VERSION ""

NS_ :

BS_:

BU_: BMS Charger

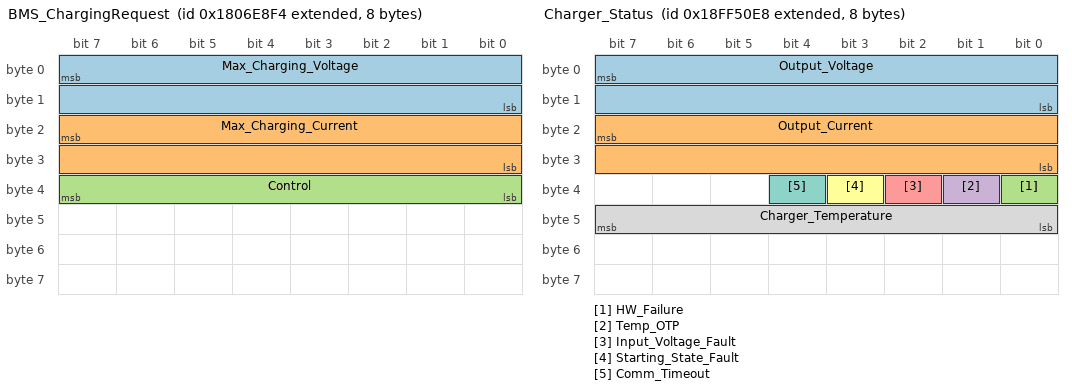
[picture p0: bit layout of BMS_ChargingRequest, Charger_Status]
BO_ 2550589684 BMS_ChargingRequest: 8 BMS
 SG_ Max_Charging_Voltage : 7|16@0+ (0.1,0) [0|6553.5] "V"  Charger
 SG_ Max_Charging_Current : 23|16@0+ (0.1,0) [0|6553.5] "A"  Charger
 SG_ Control : 32|8@1+ (1,0) [0|255] ""  Charger

BO_ 2566869224 Charger_Status: 8 Charger
 SG_ Output_Voltage : 7|16@0+ (0.1,0) [0|6553.5] "V"  BMS
 SG_ Output_Current : 23|16@0+ (0.1,0) [0|6553.5] "A"  BMS
 SG_ HW_Failure : 32|1@1+ (1,0) [0|1] ""  BMS
 SG_ Temp_OTP : 33|1@1+ (1,0) [0|1] ""  BMS
 SG_ Input_Voltage_Fault : 34|1@1+ (1,0) [0|1] ""  BMS
 SG_ Starting_State_Fault : 35|1@1+ (1,0) [0|1] ""  BMS
 SG_ Comm_Timeout : 36|1@1+ (1,0) [0|1] ""  BMS
 SG_ Charger_Temperature : 40|8@1+ (1,-40) [-40|215] "degC"  BMS

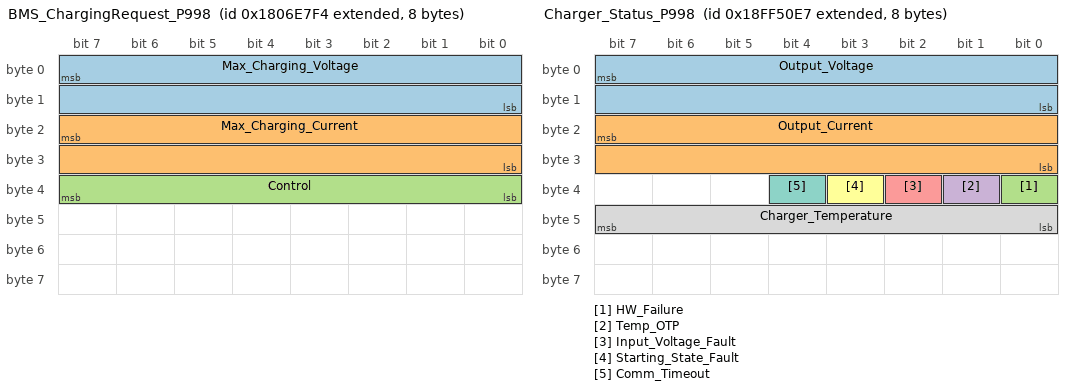
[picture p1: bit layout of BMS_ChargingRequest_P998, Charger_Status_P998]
BO_ 2550589428 BMS_ChargingRequest_P998: 8 BMS
 SG_ Max_Charging_Voltage : 7|16@0+ (0.1,0) [0|6553.5] "V"  Charger
 SG_ Max_Charging_Current : 23|16@0+ (0.1,0) [0|6553.5] "A"  Charger
 SG_ Control : 32|8@1+ (1,0) [0|255] ""  Charger

BO_ 2566869223 Charger_Status_P998: 8 Charger
 SG_ Output_Voltage : 7|16@0+ (0.1,0) [0|6553.5] "V"  BMS
 SG_ Output_Current : 23|16@0+ (0.1,0) [0|6553.5] "A"  BMS
 SG_ HW_Failure : 32|1@1+ (1,0) [0|1] ""  BMS
 SG_ Temp_OTP : 33|1@1+ (1,0) [0|1] ""  BMS
 SG_ Input_Voltage_Fault : 34|1@1+ (1,0) [0|1] ""  BMS
 SG_ Starting_State_Fault : 35|1@1+ (1,0) [0|1] ""  BMS
 SG_ Comm_Timeout : 36|1@1+ (1,0) [0|1] ""  BMS
 SG_ Charger_Temperature : 40|8@1+ (1,-40) [-40|215] "degC"  BMS

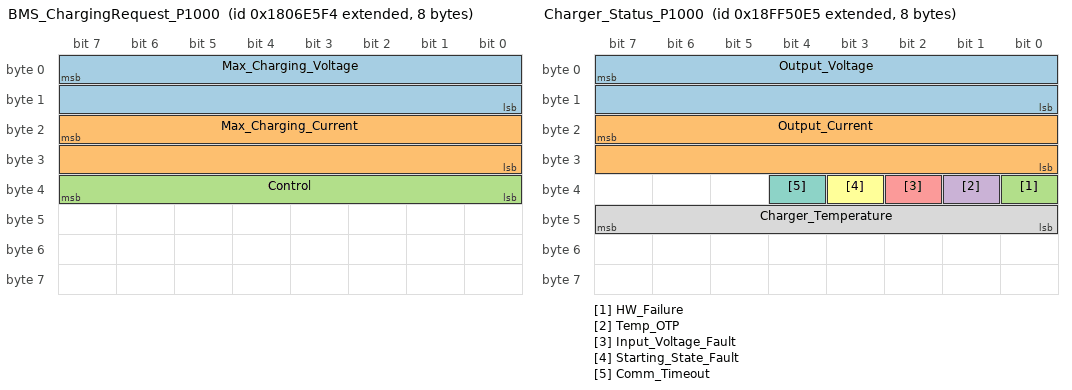
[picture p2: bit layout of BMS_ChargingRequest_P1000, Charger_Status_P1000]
BO_ 2550588916 BMS_ChargingRequest_P1000: 8 BMS
 SG_ Max_Charging_Voltage : 7|16@0+ (0.1,0) [0|6553.5] "V"  Charger
 SG_ Max_Charging_Current : 23|16@0+ (0.1,0) [0|6553.5] "A"  Charger
 SG_ Control : 32|8@1+ (1,0) [0|255] ""  Charger

BO_ 2566869221 Charger_Status_P1000: 8 Charger
 SG_ Output_Voltage : 7|16@0+ (0.1,0) [0|6553.5] "V"  BMS
 SG_ Output_Current : 23|16@0+ (0.1,0) [0|6553.5] "A"  BMS
 SG_ HW_Failure : 32|1@1+ (1,0) [0|1] ""  BMS
 SG_ Temp_OTP : 33|1@1+ (1,0) [0|1] ""  BMS
 SG_ Input_Voltage_Fault : 34|1@1+ (1,0) [0|1] ""  BMS
 SG_ Starting_State_Fault : 35|1@1+ (1,0) [0|1] ""  BMS
 SG_ Comm_Timeout : 36|1@1+ (1,0) [0|1] ""  BMS
 SG_ Charger_Temperature : 40|8@1+ (1,-40) [-40|215] "degC"  BMS

CM_ BU_ BMS "Battery Management System";
CM_ BU_ Charger "EV Europe AC/DC Charger";
CM_ BO_ 2550589684 "BMS to Charger: charging setpoints. CAN ID 0x1806E8F4 (Protocol 997/1197). Cycle 1000ms.";
CM_ SG_ 2550589684 Max_Charging_Voltage "Max allowable charging terminal voltage. Resolution 0.1V/bit. e.g. Vset=3201 -> 320.1V";
CM_ SG_ 2550589684 Max_Charging_Current "Max allowable charging current. Resolution 0.1A/bit. e.g. Iset=582 -> 58.2A";
CM_ SG_ 2550589684 Control "0: Starting to charge 1 (Battery protection, charger close output)";
CM_ BO_ 2566869224 "Charger to BMS: actual output status. CAN ID 0x18FF50E8 (Protocol 997/1197). Cycle 1000ms.";
CM_ SG_ 2566869224 Output_Voltage "Actual charger output voltage. Resolution 0.1V/bit. e.g. Vout=3201 -> 320.1V";
CM_ SG_ 2566869224 Output_Current "Actual charger output current. Resolution 0.1A/bit. e.g. Iout=582 -> 58.2A. Highest byte mark: 0=Charging, 1=Discharging";
CM_ SG_ 2566869224 HW_Failure "Bit0 STATUS: Hardware failure flag";
CM_ SG_ 2566869224 Temp_OTP "Bit1 STATUS: Temperature of charger flag";
CM_ SG_ 2566869224 Input_Voltage_Fault "Bit2 STATUS: Input voltage flag";
CM_ SG_ 2566869224 Starting_State_Fault "Bit3 STATUS: Starting state (battery connection)";
CM_ SG_ 2566869224 Comm_Timeout "Bit4 STATUS: Communication timeout flag";
CM_ SG_ 2566869224 Charger_Temperature "Charger internal temperature. Offset -40 degC.";
CM_ BO_ 2550589428 "BMS to Charger: charging setpoints. CAN ID 0x1806E7F4 (Protocol 998/1198). Cycle 1000ms.";
CM_ BO_ 2566869223 "Charger to BMS: actual output status. CAN ID 0x18FF50E7 (Protocol 998/1198). Cycle 1000ms.";
CM_ BO_ 2550588916 "BMS to Charger: charging setpoints. CAN ID 0x1806E5F4 (Protocol 1000/1200). Cycle 1000ms.";
CM_ BO_ 2566869221 "Charger to BMS: actual output status. CAN ID 0x18FF50E5 (Protocol 1000/1200). Cycle 1000ms.";
BA_DEF_ BO_  "GenMsgCycleTime" INT 0 10000;
BA_DEF_DEF_  "GenMsgCycleTime" 0;
BA_ "GenMsgCycleTime" BO_ 2550589684 1000;
BA_ "GenMsgCycleTime" BO_ 2566869224 1000;
BA_ "GenMsgCycleTime" BO_ 2550589428 1000;
BA_ "GenMsgCycleTime" BO_ 2566869223 1000;
BA_ "GenMsgCycleTime" BO_ 2550588916 1000;
BA_ "GenMsgCycleTime" BO_ 2566869221 1000;
VAL_ 2566869224 HW_Failure 0 "Normal" 1 "Hardware_Failure" ;
VAL_ 2566869224 Temp_OTP 0 "Normal" 1 "Over_Temperature_Protection" ;
VAL_ 2566869224 Input_Voltage_Fault 0 "Normal_Input_Voltage" 1 "Incorrect_Input_Voltage_Charger_Stop" ;
VAL_ 2566869224 Starting_State_Fault 0 "Normal_Battery_Connected" 1 "Battery_Disconnecting_or_Reverse" ;
VAL_ 2566869224 Comm_Timeout 0 "Normal_Communication" 1 "Receiving_Timeout" ;
VAL_ 2566869223 HW_Failure 0 "Normal" 1 "Hardware_Failure" ;
VAL_ 2566869223 Temp_OTP 0 "Normal" 1 "Over_Temperature_Protection" ;
VAL_ 2566869223 Input_Voltage_Fault 0 "Normal_Input_Voltage" 1 "Incorrect_Input_Voltage_Charger_Stop" ;
VAL_ 2566869223 Starting_State_Fault 0 "Normal_Battery_Connected" 1 "Battery_Disconnecting_or_Reverse" ;
VAL_ 2566869223 Comm_Timeout 0 "Normal_Communication" 1 "Receiving_Timeout" ;
VAL_ 2566869221 HW_Failure 0 "Normal" 1 "Hardware_Failure" ;
VAL_ 2566869221 Temp_OTP 0 "Normal" 1 "Over_Temperature_Protection" ;
VAL_ 2566869221 Input_Voltage_Fault 0 "Normal_Input_Voltage" 1 "Incorrect_Input_Voltage_Charger_Stop" ;
VAL_ 2566869221 Starting_State_Fault 0 "Normal_Battery_Connected" 1 "Battery_Disconnecting_or_Reverse" ;
VAL_ 2566869221 Comm_Timeout 0 "Normal_Communication" 1 "Receiving_Timeout" ;
